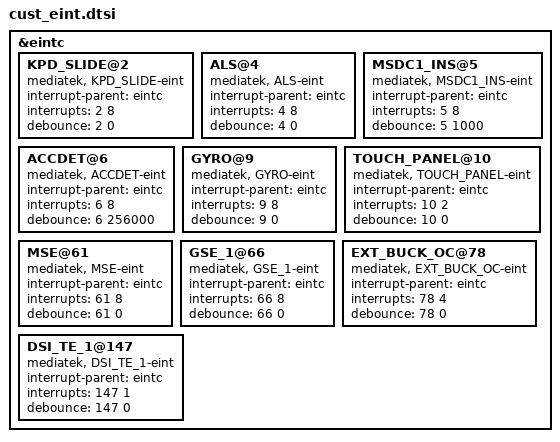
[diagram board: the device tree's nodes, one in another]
/*
 * Generated by MTK SP Drv_CodeGen Version 03.13.6  for MT6753. Copyright MediaTek Inc. (C) 2013.
 * Tue Mar 28 19:33:46 2017
 * Do Not Modify the File.
 */

/*************************
 * EINT DTSI File
*************************/

&eintc {
	KPD_SLIDE@2 {
		compatible = "mediatek, KPD_SLIDE-eint";
		interrupt-parent = <&eintc>;
		interrupts = <2 8>;
		debounce = <2 0>;
	};

	ALS@4 {
		compatible = "mediatek, ALS-eint";
		interrupt-parent = <&eintc>;
		interrupts = <4 8>;
		debounce = <4 0>;
	};

	MSDC1_INS@5 {
		compatible = "mediatek, MSDC1_INS-eint";
		interrupt-parent = <&eintc>;
		interrupts = <5 8>;
		debounce = <5 1000>;
	};

	ACCDET@6 {
		compatible = "mediatek, ACCDET-eint";
		interrupt-parent = <&eintc>;
		interrupts = <6 8>;
		debounce = <6 256000>;
	};

	GYRO@9 {
		compatible = "mediatek, GYRO-eint";
		interrupt-parent = <&eintc>;
		interrupts = <9 8>;
		debounce = <9 0>;
	};

	TOUCH_PANEL@10 {
		compatible = "mediatek, TOUCH_PANEL-eint";
		interrupt-parent = <&eintc>;
		interrupts = <10 2>;
		debounce = <10 0>;
	};

	MSE@61 {
		compatible = "mediatek, MSE-eint";
		interrupt-parent = <&eintc>;
		interrupts = <61 8>;
		debounce = <61 0>;
	};

	GSE_1@66 {
		compatible = "mediatek, GSE_1-eint";
		interrupt-parent = <&eintc>;
		interrupts = <66 8>;
		debounce = <66 0>;
	};

	EXT_BUCK_OC@78 {
		compatible = "mediatek, EXT_BUCK_OC-eint";
		interrupt-parent = <&eintc>;
		interrupts = <78 4>;
		debounce = <78 0>;
	};

	DSI_TE_1@147 {
		compatible = "mediatek, DSI_TE_1-eint";
		interrupt-parent = <&eintc>;
		interrupts = <147 1>;
		debounce = <147 0>;
	};

};
